# MLDR187 register map
File version: 1.3
CPU: MLDR178, little endian
Registers are 32-bit, read-write, no defined reset value unless marked. A register's access mark holds for its fields unless they carry their own. Offsets are from the block's base; [hi:lo] are bit positions; {n}, {i} and the like mark numbered series; 'fields as' and 'values as' point back to an identical list.

## BKP — BKP description
Base 0x40060000
0x00 WPR — WPR description
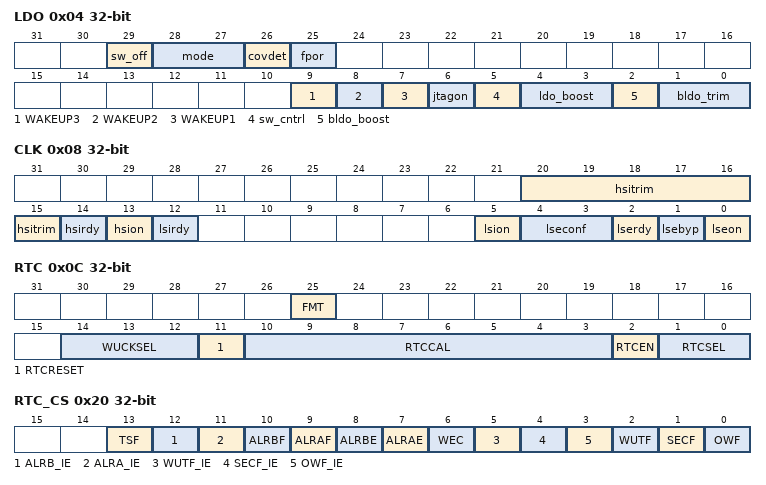
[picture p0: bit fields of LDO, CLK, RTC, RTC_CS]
0x04 LDO — LDO description
  [29] sw_off — sw_off description
  [28:27] mode — mode description
  [26] covdet — covdet description
  [25] fpor — fpor description
  [9] WAKEUP3 ro — WAKEUP3 description
  [8] WAKEUP2 ro — WAKEUP2 description
  [7] WAKEUP1 ro — WAKEUP1 description
  [6] jtagon — jtagon description
  [5] sw_cntrl — sw_cntrl description
  [4:3] ldo_boost — ldo_boost description
  [2] bldo_boost — bldo_boost description
  [1:0] bldo_trim — bldo_trim description
0x08 CLK — CLK description
  [20:15] hsitrim — hsitrim description
  [14] hsirdy ro — hsirdy description
  [13] hsion — hsion description
  [12] lsirdy ro — lsirdy description
  [5] lsion — lsion description
  [4:3] lseconf — lseconf description
  [2] lserdy ro — lserdy description
  [1] lsebyp — lsebyp description
  [0] lseon — lseon description
0x0C RTC — RTC description
  [25] FMT — FMT description
  [14:12] WUCKSEL — WUCKSEL description
  [11] RTCRESET — RTCRESET description
  [10:3] RTCCAL — RTCCAL description
  [2] RTCEN — RTCEN description
  [1:0] RTCSEL — RTCSEL description
0x10 RTC_WUTR — RTC_WUTR description
0x14 RTC_PREDIV_S — RTC_PREDIV_S description
  [19:0] RTCDIV — RTCDIV description
0x18 RTC_PRL — RTC_PRL description
  [19:0] RTCPRL — RTCPRL description
0x1C RTC_ALRM — RTC_ALRM description
0x20 RTC_CS — RTC_CS description
  [13] TSF — TSF description
  [12] ALRB_IE — ALRB_IE description
  [11] ALRA_IE — ALRA_IE description
  [10] ALRBF — ALRBF description
  [9] ALRAF — ALRAF description
  [8] ALRBE — ALRBE description
  [7] ALRAE — ALRAE description
  [6] WEC ro — WEC description
  [5] WUTF_IE — WUTF_IE description
  [4] SECF_IE — SECF_IE description
  [3] OWF_IE — OWF_IE description
  [2] WUTF — WUTF description
  [1] SECF — SECF description
  [0] OWF — OWF description
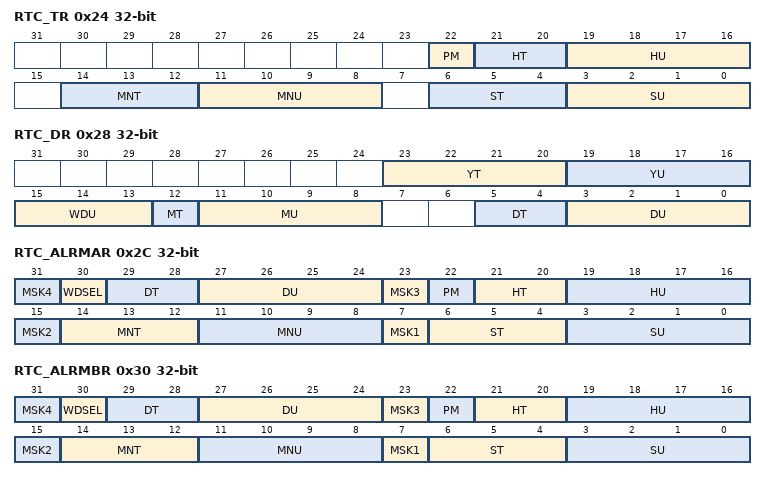
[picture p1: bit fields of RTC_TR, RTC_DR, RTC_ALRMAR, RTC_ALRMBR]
0x24 RTC_TR — RTC_TR description
  [22] PM — PM description
  [21:20] HT — HT description
  [19:16] HU — HU description
  [14:12] MNT — MNT description
  [11:8] MNU — MNU description
  [6:4] ST — ST description
  [3:0] SU — SU description
0x28 RTC_DR — RTC_DR description
  [23:20] YT — YT description
  [19:16] YU — YU description
  [15:13] WDU — WDU description
  [12] MT — MT description
  [11:8] MU — MU description
  [5:4] DT — DT description
  [3:0] DU — DU description
0x2C RTC_ALRMAR — RTC_ALRMAR description
  [8n-1] MSK{n} (n=1..4) — MSK{n} description
  [30] WDSEL — WDSEL description
  [29:28] DT — DT description
  [27:24] DU — DU description
  [22] PM — PM description
  [21:20] HT — HT description
  [19:16] HU — HU description
  [14:12] MNT — MNT description
  [11:8] MNU — MNU description
  [6:4] ST — ST description
  [3:0] SU — SU description
0x30 RTC_ALRMBR — RTC_ALRMBR description
  fields as RTC_ALRMAR
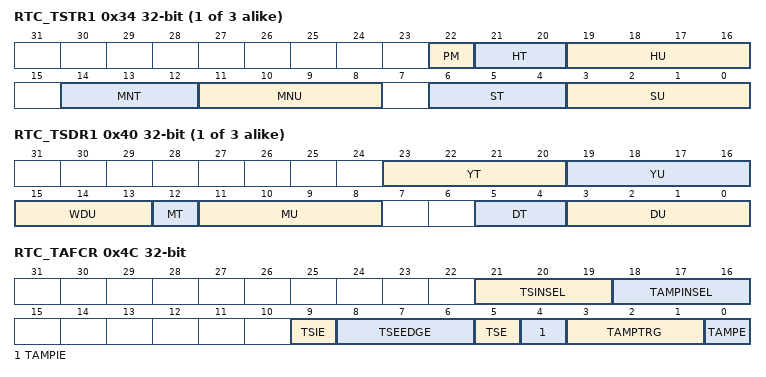
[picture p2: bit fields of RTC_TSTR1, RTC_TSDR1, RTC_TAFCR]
{0x30+4i} RTC_TSTR{i} (i=1..3) — RTC_TSTR{i} description
  fields as RTC_TR
{0x3C+4i} RTC_TSDR{i} (i=1..3) — RTC_TSDR{i} description
  fields as RTC_DR
0x4C RTC_TAFCR — RTC_TAFCR description
  [21:19] TSINSEL ro — TSINSEL description
  [18:16] TAMPINSEL ro — TAMPINSEL description
  [9] TSIE — TSIE description
  [8:6] TSEEDGE — TSEEDGE description
  [5] TSE — TSE description
  [4] TAMPIE — TAMPIE description
  [3:1] TAMPTRG — TAMPTRG description
  [0] TAMPE — TAMPE description

## PBYTE — PBYTE description
Base 0x60028000
{0x0+4i} TRM_{i:02} (i=0..15) — Transformation register {i}
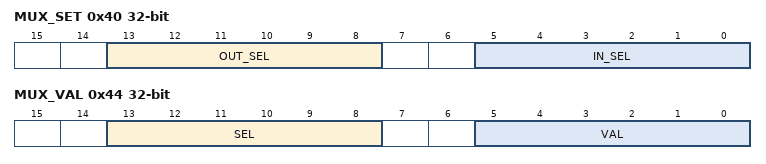
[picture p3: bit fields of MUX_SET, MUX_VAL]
0x40 MUX_SET — Transformation setup register
  [13:8] OUT_SEL wo — OUT_SEL description
  [5:0] IN_SEL wo — IN_SEL description
0x44 MUX_VAL — Transformation value register
  [13:8] SEL wo — SEL description
  [5:0] VAL ro — VAL description

## SBLOCK0 — SBLOCK0 description
Base 0x60008000
Same registers: SBLOCK1 0x6000C000, SBLOCK2 0x60010000, SBLOCK3 0x60014000, SBLOCK4 0x60018000, SBLOCK5 0x6001C000, SBLOCK6 0x60020000, SBLOCK7 0x60024000
{0x0+4i} TRM_{i:02} (i=0..3) — Transformation register {i}
{0x0+4i} TRM_{i:02} (i=4..7) — Transformation register {i-4}
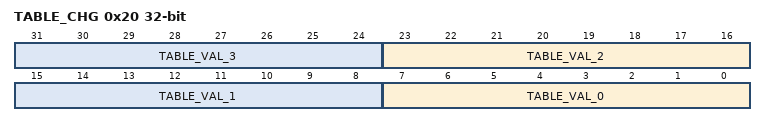
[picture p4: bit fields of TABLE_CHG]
0x20 TABLE_CHG — Table change register
  [8n+7:8n] TABLE_VAL_{n} (n=0..3) — TABLE_VAL_{n} description
0x24 M_SCTRL — Memory special control
